# HDSC_HC32F460KEUA register map
Vendor: HDSC Co.,Ltd.; Series: ARMCM4; File version: 1.0
CPU: CM4 r0p1, little endian, MPU, FPU, 4 interrupt priority bits
Registers are 32-bit, read-write, reset 0x0 unless marked. A register's access mark holds for its fields unless they carry their own. Offsets are from the block's base; [hi:lo] are bit positions; {n}, {i} and the like mark numbered series.

## SRAMC
Base 0x40050800
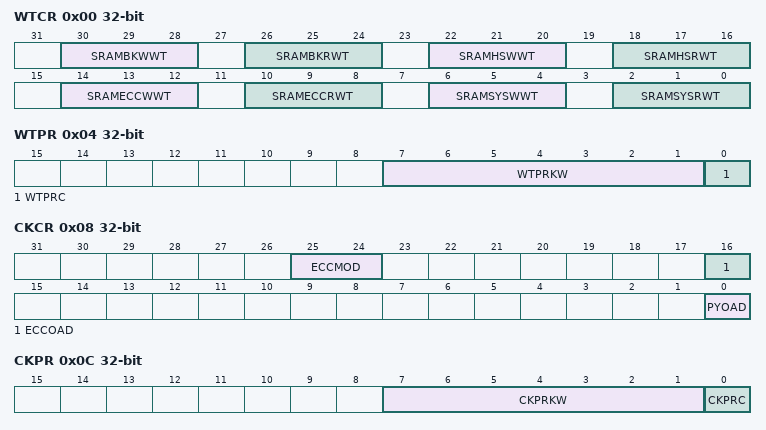
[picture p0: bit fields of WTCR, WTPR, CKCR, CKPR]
0x00 WTCR
  [30:28] SRAMBKWWT, [26:24] SRAMBKRWT, [22:20] SRAMHSWWT, [18:16] SRAMHSRWT, [14:12] SRAMECCWWT, [10:8] SRAMECCRWT, [6:4] SRAMSYSWWT, [2:0] SRAMSYSRWT
0x04 WTPR
  [7:1] WTPRKW, [0] WTPRC
0x08 CKCR
  [25:24] ECCMOD, [16] ECCOAD, [0] PYOAD
0x0C CKPR
  [7:1] CKPRKW, [0] CKPRC
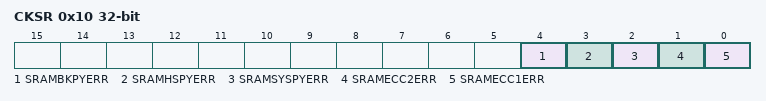
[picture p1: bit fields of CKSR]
0x10 CKSR
  [4] SRAMBKPYERR, [3] SRAMHSPYERR, [2] SRAMSYSPYERR, [1] SRAMECC2ERR, [0] SRAMECC1ERR

## SWDT
Base 0x40049400
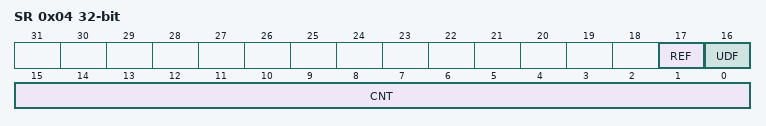
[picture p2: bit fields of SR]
0x04 SR ro
  [17] REF rw, [16] UDF rw, [15:0] CNT
0x08 RR ro
  [15:0] RF

## TMR01 — desc TMR0
Base 0x40024000
Same registers: TMR02 0x40024400
0x00 CNTAR
  [15:0] CNTA
0x04 CNTBR
  [15:0] CNTB
0x08 CMPAR reset 0xFFFF
  [15:0] CMPA
0x0C CMPBR reset 0xFFFF
  [15:0] CMPB
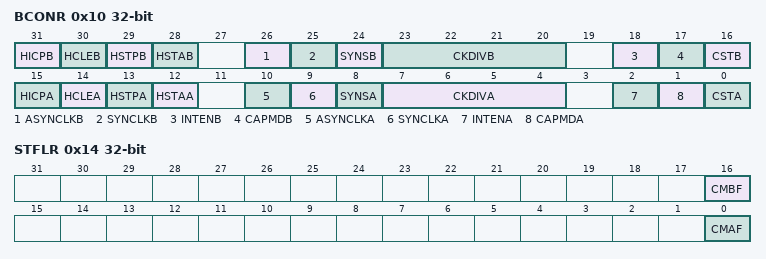
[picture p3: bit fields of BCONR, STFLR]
0x10 BCONR
  [31] HICPB, [30] HCLEB, [29] HSTPB, [28] HSTAB, [26] ASYNCLKB, [25] SYNCLKB, [24] SYNSB, [23:20] CKDIVB, [18] INTENB, [17] CAPMDB, [16] CSTB, [15] HICPA, [14] HCLEA, [13] HSTPA, [12] HSTAA, [10] ASYNCLKA, [9] SYNCLKA, [8] SYNSA, [7:4] CKDIVA, [2] INTENA, [1] CAPMDA, [0] CSTA
0x14 STFLR
  [16] CMBF, [0] CMAF

## TMR4_CR
Base 0x40055408
0x00 ECER1 16-bit
  [1:0] EMBVAL
0x04 ECER2 16-bit
  [1:0] EMBVAL
0x08 ECER3 16-bit
  [1:0] EMBVAL

## TMR61 — desc TMR6
Base 0x40018000
Same registers: TMR62 0x40018400, TMR63 0x40018800
0x00 CNTER
  [15:0] CNT
0x04 PERAR reset 0xFFFF
  [15:0] PERA
0x08 PERBR reset 0xFFFF
  [15:0] PERB
0x0C PERCR reset 0xFFFF
  [15:0] PERC
0x10 GCMAR reset 0xFFFF
  [15:0] GCMA
0x14 GCMBR reset 0xFFFF
  [15:0] GCMB
0x18 GCMCR reset 0xFFFF
  [15:0] GCMC
0x1C GCMDR reset 0xFFFF
  [15:0] GCMD
0x20 GCMER reset 0xFFFF
  [15:0] GCME
0x24 GCMFR reset 0xFFFF
  [15:0] GCMF
0x28 SCMAR reset 0xFFFF
  [15:0] SCMA
0x2C SCMBR reset 0xFFFF
  [15:0] SCMB
0x30 SCMCR reset 0xFFFF
  [15:0] SCMC
0x34 SCMDR reset 0xFFFF
  [15:0] SCMD
0x38 SCMER reset 0xFFFF
  [15:0] SCME
0x3C SCMFR reset 0xFFFF
  [15:0] SCMF
0x40 DTUAR reset 0xFFFF
  [15:0] DTUA
0x44 DTDAR reset 0xFFFF
  [15:0] DTDA
0x48 DTUBR reset 0xFFFF
  [15:0] DTUB
0x4C DTDBR reset 0xFFFF
  [15:0] DTDB
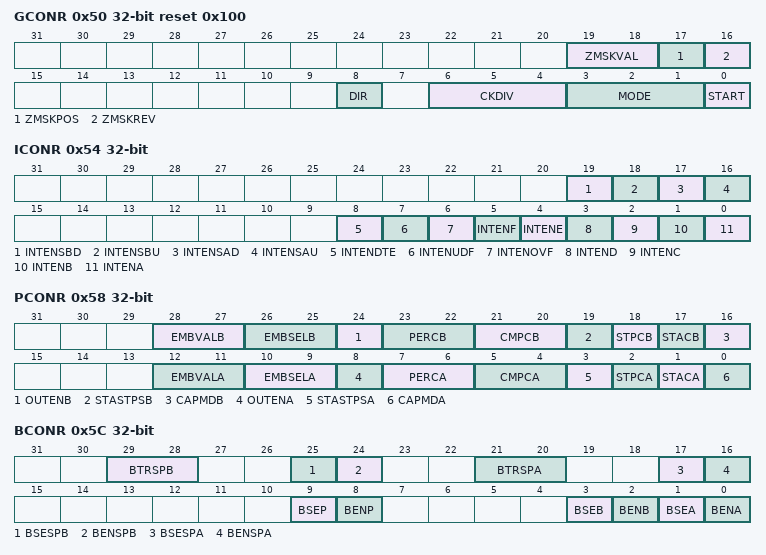
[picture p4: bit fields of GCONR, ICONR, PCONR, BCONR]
0x50 GCONR reset 0x100
  [19:18] ZMSKVAL, [17] ZMSKPOS, [16] ZMSKREV, [8] DIR, [6:4] CKDIV, [3:1] MODE, [0] START
0x54 ICONR
  [19] INTENSBD, [18] INTENSBU, [17] INTENSAD, [16] INTENSAU, [8] INTENDTE, [7] INTENUDF, [6] INTENOVF, [5] INTENF, [4] INTENE, [3] INTEND, [2] INTENC, [1] INTENB, [0] INTENA
0x58 PCONR
  [28:27] EMBVALB, [26:25] EMBSELB, [24] OUTENB, [23:22] PERCB, [21:20] CMPCB, [19] STASTPSB, [18] STPCB, [17] STACB, [16] CAPMDB, [12:11] EMBVALA, [10:9] EMBSELA, [8] OUTENA, [7:6] PERCA, [5:4] CMPCA, [3] STASTPSA, [2] STPCA, [1] STACA, [0] CAPMDA
0x5C BCONR
  [29:28] BTRSPB, [25] BSESPB, [24] BENSPB, [21:20] BTRSPA, [17] BSESPA, [16] BENSPA, [9] BSEP, [8] BENP, [3] BSEB, [2] BENB, [1] BSEA, [0] BENA
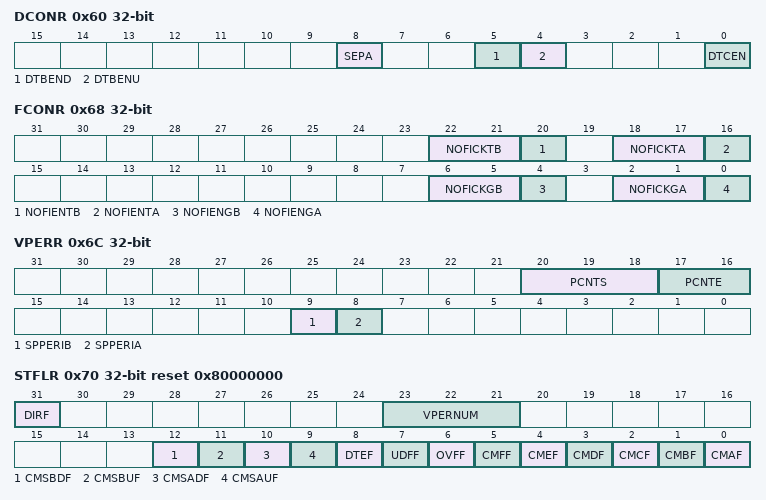
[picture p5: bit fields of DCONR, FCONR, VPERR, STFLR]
0x60 DCONR
  [8] SEPA, [5] DTBEND, [4] DTBENU, [0] DTCEN
0x68 FCONR
  [22:21] NOFICKTB, [20] NOFIENTB, [18:17] NOFICKTA, [16] NOFIENTA, [6:5] NOFICKGB, [4] NOFIENGB, [2:1] NOFICKGA, [0] NOFIENGA
0x6C VPERR
  [20:18] PCNTS, [17:16] PCNTE, [9] SPPERIB, [8] SPPERIA
0x70 STFLR reset 0x80000000
  [31] DIRF ro, [23:21] VPERNUM ro, [12] CMSBDF, [11] CMSBUF, [10] CMSADF, [9] CMSAUF, [8] DTEF ro, [7] UDFF, [6] OVFF, [5] CMFF, [4] CMEF, [3] CMDF, [2] CMCF, [1] CMBF, [0] CMAF
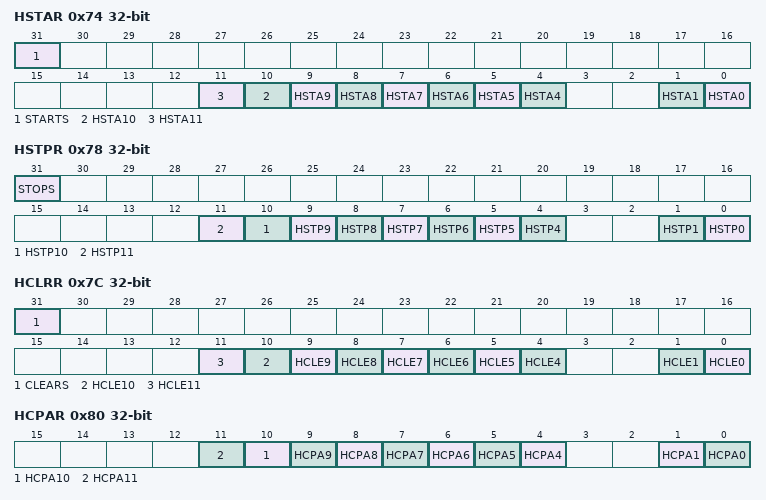
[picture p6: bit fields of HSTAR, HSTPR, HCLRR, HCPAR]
0x74 HSTAR
  [31] STARTS, [n] HSTA{n} (n=4..11), [1] HSTA1, [0] HSTA0
0x78 HSTPR
  [31] STOPS, [n] HSTP{n} (n=4..11), [1] HSTP1, [0] HSTP0
0x7C HCLRR
  [31] CLEARS, [n] HCLE{n} (n=4..11), [1] HCLE1, [0] HCLE0
0x80 HCPAR
  [n] HCPA{n} (n=4..11), [1] HCPA1, [0] HCPA0
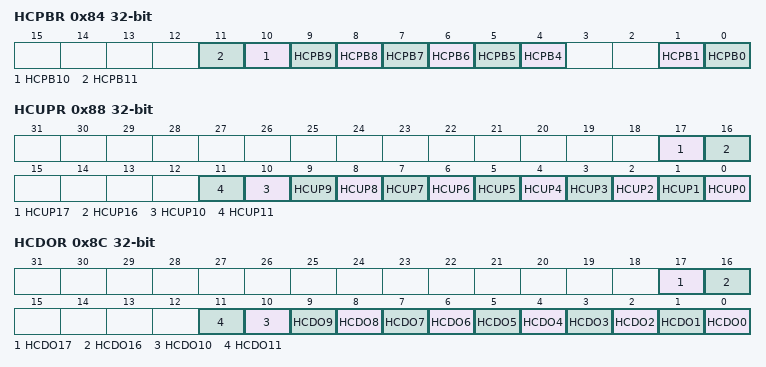
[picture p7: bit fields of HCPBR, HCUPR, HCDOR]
0x84 HCPBR
  [n] HCPB{n} (n=4..11), [1] HCPB1, [0] HCPB0
0x88 HCUPR
  [17] HCUP17, [16] HCUP16, [n] HCUP{n} (n=0..11)
0x8C HCDOR
  [17] HCDO17, [16] HCDO16, [n] HCDO{n} (n=0..11)

## TMR6_CR
Base 0x40018000; alternate view of TMR61
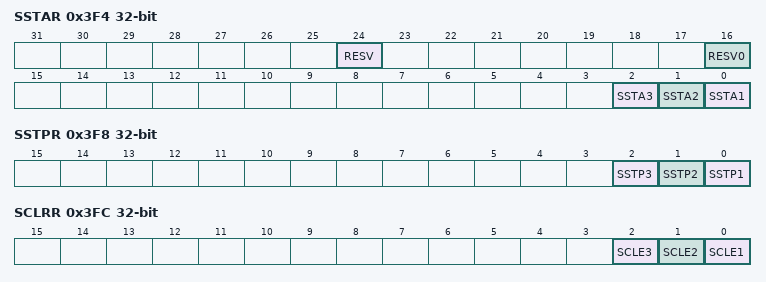
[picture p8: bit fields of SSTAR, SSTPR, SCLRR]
0x3F4 SSTAR (reset mask 0x7)
  [24] RESV, [16] RESV0, [2] SSTA3, [1] SSTA2, [0] SSTA1
0x3F8 SSTPR
  [2] SSTP3, [1] SSTP2, [0] SSTP1
0x3FC SCLRR
  [2] SCLE3, [1] SCLE2, [0] SCLE1

## TMRA1 — desc TMRA
Base 0x40015000
Same registers: TMRA2 0x40015400, TMRA3 0x40015800, TMRA4 0x40015C00, TMRA5 0x40016000, TMRA6 0x40016400
0x00 CNTER
  [15:0] CNT
0x04 PERAR reset 0xFFFF
  [15:0] PER
{0x3C+4i} CMPAR{i} reset 0xFFFF (i=1..8)
  [15:0] CMP
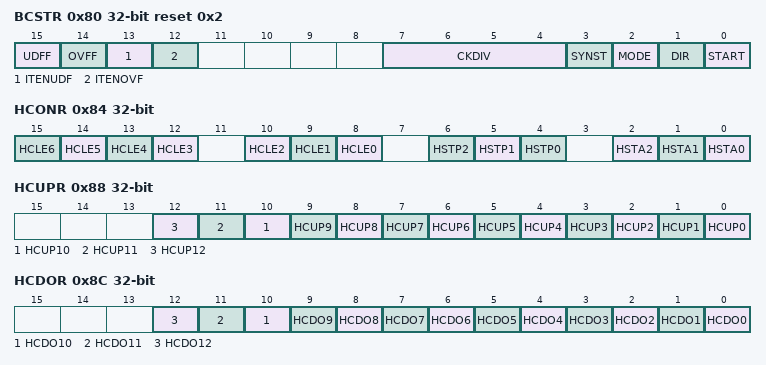
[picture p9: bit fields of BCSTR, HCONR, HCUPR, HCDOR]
0x80 BCSTR reset 0x2
  [15] UDFF, [14] OVFF, [13] ITENUDF, [12] ITENOVF, [7:4] CKDIV, [3] SYNST, [2] MODE, [1] DIR, [0] START
0x84 HCONR
  [n+9] HCLE{n} (n=3..6), [10] HCLE2, [9] HCLE1, [8] HCLE0, [6] HSTP2, [5] HSTP1, [4] HSTP0, [2] HSTA2, [1] HSTA1, [0] HSTA0
0x88 HCUPR
  [n] HCUP{n} (n=0..12)
0x8C HCDOR
  [n] HCDO{n} (n=0..12)
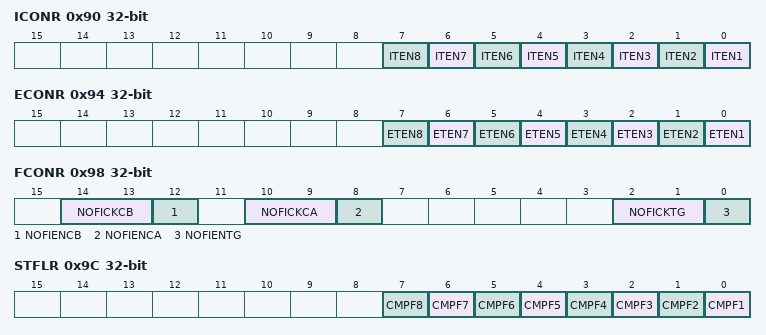
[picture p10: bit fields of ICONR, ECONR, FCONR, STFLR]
0x90 ICONR
  [n-1] ITEN{n} (n=1..8)
0x94 ECONR
  [n-1] ETEN{n} (n=1..8)
0x98 FCONR
  [14:13] NOFICKCB, [12] NOFIENCB, [10:9] NOFICKCA, [8] NOFIENCA, [2:1] NOFICKTG, [0] NOFIENTG
0x9C STFLR
  [n-1] CMPF{n} (n=1..8)
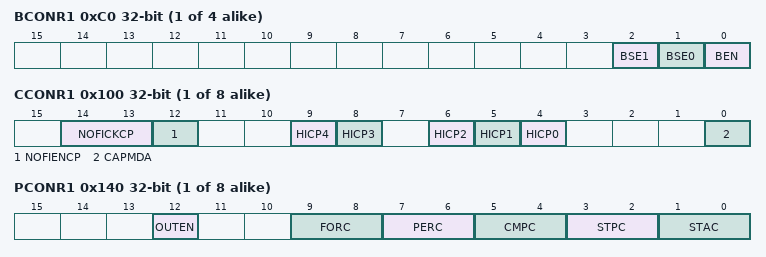
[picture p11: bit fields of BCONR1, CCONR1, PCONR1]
{0xB8+8i} BCONR{i} (i=1..4)
  [2] BSE1, [1] BSE0, [0] BEN
{0xFC+4i} CCONR{i} (i=1..8)
  [14:13] NOFICKCP, [12] NOFIENCP, [9] HICP4, [8] HICP3, [6] HICP2, [5] HICP1, [4] HICP0, [0] CAPMDA
{0x13C+4i} PCONR{i} (i=1..8)
  [12] OUTEN, [9:8] FORC, [7:6] PERC, [5:4] CMPC, [3:2] STPC, [1:0] STAC

## TRNG
Base 0x40041000
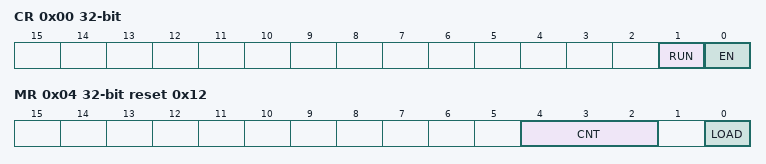
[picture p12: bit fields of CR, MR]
0x00 CR
  [1] RUN, [0] EN
0x04 MR reset 0x12
  [4:2] CNT, [0] LOAD
0x0C DR0 ro reset 0x8000000
0x10 DR1 ro reset 0x8000200

## USART1 — desc USART
Base 0x4001D000
Same registers: USART2 0x4001D400, USART3 0x40021000, USART4 0x40021400
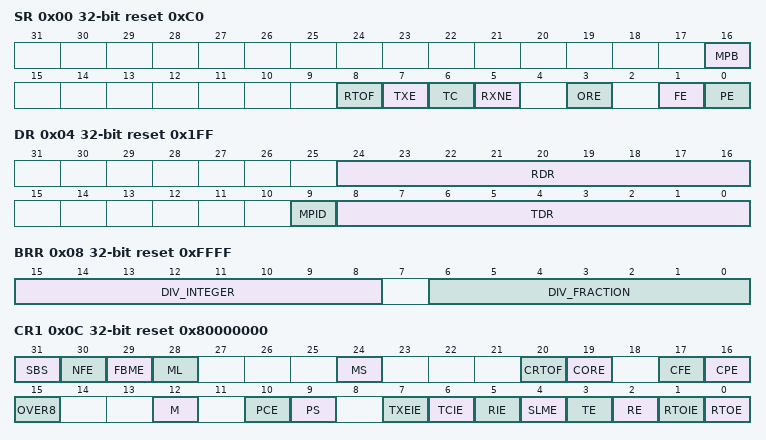
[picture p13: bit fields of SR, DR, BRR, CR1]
0x00 SR ro reset 0xC0
  [16] MPB, [8] RTOF, [7] TXE, [6] TC, [5] RXNE, [3] ORE, [1] FE, [0] PE
0x04 DR reset 0x1FF
  [24:16] RDR, [9] MPID, [8:0] TDR
0x08 BRR reset 0xFFFF
  [15:8] DIV_INTEGER, [6:0] DIV_FRACTION
0x0C CR1 reset 0x80000000
  [31] SBS, [30] NFE, [29] FBME, [28] ML, [24] MS, [20] CRTOF wo, [19] CORE wo, [17] CFE wo, [16] CPE wo, [15] OVER8, [12] M, [10] PCE, [9] PS, [7] TXEIE, [6] TCIE, [5] RIE, [4] SLME, [3] TE, [2] RE, [1] RTOIE, [0] RTOE
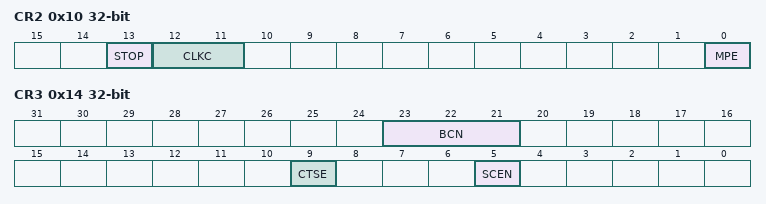
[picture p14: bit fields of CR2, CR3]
0x10 CR2
  [13] STOP, [12:11] CLKC, [0] MPE
0x14 CR3
  [23:21] BCN, [9] CTSE, [5] SCEN
0x18 PR
  [1:0] PSC

## WDT
Base 0x40049000
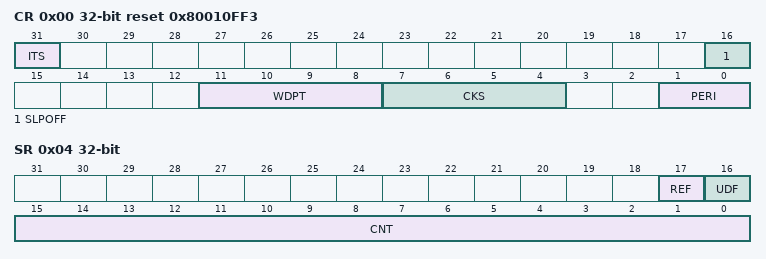
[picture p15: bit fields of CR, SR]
0x00 CR reset 0x80010FF3
  [31] ITS, [16] SLPOFF, [11:8] WDPT, [7:4] CKS, [1:0] PERI
0x04 SR ro
  [17] REF rw, [16] UDF rw, [15:0] CNT
0x08 RR ro
  [15:0] RF

## WKTM
Base 0x4004C400
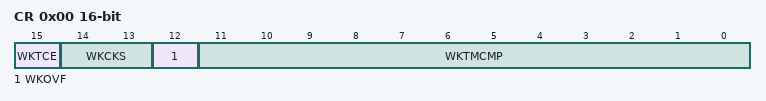
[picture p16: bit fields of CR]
0x00 CR 16-bit
  [15] WKTCE, [14:13] WKCKS, [12] WKOVF, [11:0] WKTMCMP
